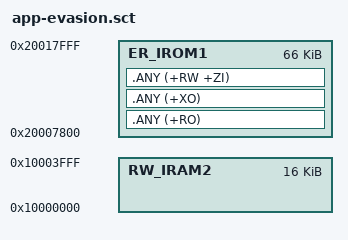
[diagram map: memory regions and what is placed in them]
; *************************************************************
; *** Scatter-Loading Description File generated by uVision ***
; *************************************************************

LR_IROM1 0x20007800 0x00010800  {    ; load region size_region
;  my_section 0x08036000 0x00010  {  ; load address = execution address
;    *(.my_section)
;  }
  ER_IROM1 0x20007800 0x00010800  {  ; load address = execution address
   ;*.o (RESET, +First)
   ;*(InRoot$$Sections)
   .ANY (+RO)
   .ANY (+XO)
   .ANY (+RW +ZI)
  }
   RW_IRAM2 0x10000000 0x00004000  {  ; RW data
   ;.ANY (+RW +ZI)
  }
}

